# STM32U575 register map
File version: 1.4
CPU: CM33 r0p1, little endian, MPU, FPU, 4 interrupt priority bits
Registers are 32-bit, read-write, reset 0x0 unless marked. A register's access mark holds for its fields unless they carry their own. Offsets are from the block's base; [hi:lo] are bit positions; {n}, {i} and the like mark numbered series; 'fields as' and 'values as' point back to an identical list.

## FMC
Base 0x420D0400
Same registers: SEC_FMC 0x520D0400
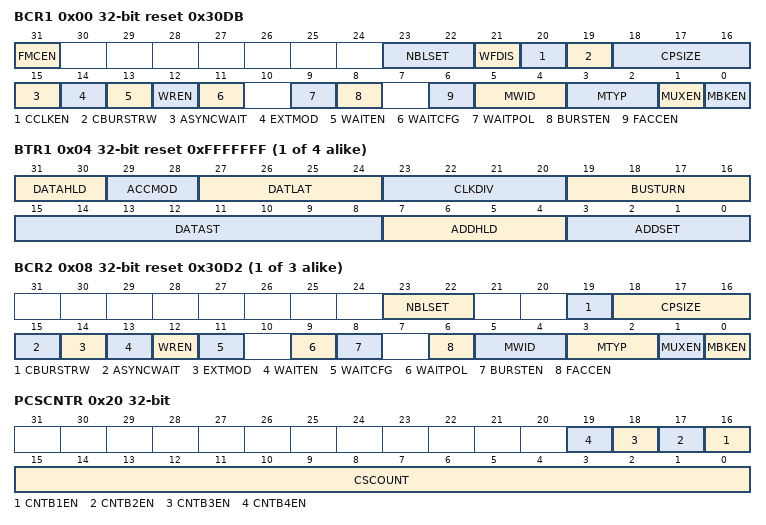
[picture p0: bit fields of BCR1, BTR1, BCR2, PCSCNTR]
0x00 BCR1 reset 0x30DB — SRAM/NOR-Flash chip-select control register for bank 1
  [31] FMCEN — FMC controller enable
  [23:22] NBLSET — Byte lane (NBL) setup
  [21] WFDIS — Write FIFO disable
  [20] CCLKEN — Continuous clock enable
  [19] CBURSTRW — Write burst enable
    0=Disabled (Write operations are always performed in asynchronous mode); 1=Enabled (Write operations are performed in synchronous mode)
  [18:16] CPSIZE — CRAM Page Size
    0=No burst split when crossing page boundary; 1=Bytes128 (128 bytes CRAM page size); 2=Bytes256 (256 bytes CRAM page size); 3=Bytes512 (512 bytes CRAM page size); 4=Bytes1024 (1024 bytes CRAM page size)
  [15] ASYNCWAIT — Wait signal during asynchronous transfers
    0=Disabled (Wait signal not used in asynchronous mode); 1=Enabled (Wait signal used even in asynchronous mode)
  [14] EXTMOD — Extended mode enable
    0=Disabled (Values inside the FMC_BWTR are not taken into account); 1=Enabled (Values inside the FMC_BWTR are taken into account)
  [13] WAITEN — Wait enable bit
    0=Disabled (Values inside the FMC_BWTR are taken into account); 1=Enabled (NWAIT signal enabled)
  [12] WREN — Write enable bit
    0=Disabled (Write operations disabled for the bank by the FMC); 1=Enabled (Write operations enabled for the bank by the FMC)
  [11] WAITCFG — Wait timing configuration
    0=BeforeWaitState (NWAIT signal is active one data cycle before wait state); 1=DuringWaitState (NWAIT signal is active during wait state)
  [9] WAITPOL — Wait signal polarity bit
    0=ActiveLow (NWAIT active low); 1=ActiveHigh (NWAIT active high)
  [8] BURSTEN — Burst enable bit
    0=Disabled (Burst mode disabled); 1=Enabled (Burst mode enabled)
  [6] FACCEN — Flash access enable
    0=Disabled (Corresponding NOR Flash memory access is disabled); 1=Enabled (Corresponding NOR Flash memory access is enabled)
  [5:4] MWID — Memory data bus width
    0=Bits8 (Memory data bus width 8 bits); 1=Bits16 (Memory data bus width 16 bits); 2=Bits32 (Memory data bus width 32 bits)
  [3:2] MTYP — Memory type
    0=SRAM (SRAM memory type); 1=PSRAM (PSRAM (CRAM) memory type); 2=Flash (NOR Flash/OneNAND Flash)
  [1] MUXEN — Address/data multiplexing enable bit
    0=Disabled (Address/Data non-multiplexed); 1=Enabled (Address/Data multiplexed on databus)
  [0] MBKEN — Memory bank enable bit
    0=Disabled (Corresponding memory bank is disabled); 1=Enabled (Corresponding memory bank is enabled)
0x04 BTR{i} (i=1..4; step 0x8) reset 0xFFFFFFF — SRAM/NOR-Flash chip-select timing register for bank {i}
  [31:30] DATAHLD — Data hold phase duration
  [29:28] ACCMOD — Access mode
    0=A (Access mode A); 1=B (Access mode B); 2=C (Access mode C); 3=D (Access mode D)
  [27:24] DATLAT — Data latency for synchronous memory
  [23:20] CLKDIV range 1..15 — Clock divide ratio (for FMC_CLK signal)
  [19:16] BUSTURN — Bus turnaround phase duration
  [15:8] DATAST range 1..255 — Data-phase duration
  [7:4] ADDHLD range 1..15 — Address-hold phase duration
  [3:0] ADDSET — Address setup phase duration
0x08 BCR{i} (i=2..4; step 0x8) reset 0x30D2 — SRAM/NOR-Flash chip-select control register for bank {i}
  [23:22] NBLSET — Byte lane (NBL) setup
  [19] CBURSTRW — Write burst enable
    values as BCR1.CBURSTRW
  [18:16] CPSIZE — CRAM Page Size
    values as BCR1.CPSIZE
  [15] ASYNCWAIT — Wait signal during asynchronous transfers
    values as BCR1.ASYNCWAIT
  [14] EXTMOD — Extended mode enable
    values as BCR1.EXTMOD
  [13] WAITEN — Wait enable bit
    values as BCR1.WAITEN
  [12] WREN — Write enable bit
    values as BCR1.WREN
  [11] WAITCFG — Wait timing configuration
    values as BCR1.WAITCFG
  [9] WAITPOL — Wait signal polarity bit
    values as BCR1.WAITPOL
  [8] BURSTEN — Burst enable bit
    values as BCR1.BURSTEN
  [6] FACCEN — Flash access enable
    values as BCR1.FACCEN
  [5:4] MWID — Memory data bus width
    values as BCR1.MWID
  [3:2] MTYP — Memory type
    values as BCR1.MTYP
  [1] MUXEN — Address/data multiplexing enable bit
    values as BCR1.MUXEN
  [0] MBKEN — Memory bank enable bit
    values as BCR1.MBKEN
0x20 PCSCNTR — PSRAM chip select counter register
  [n+15] CNTB{n}EN (n=1..4) — Counter Bank {n} enable
  [15:0] CSCOUNT — Chip select counter
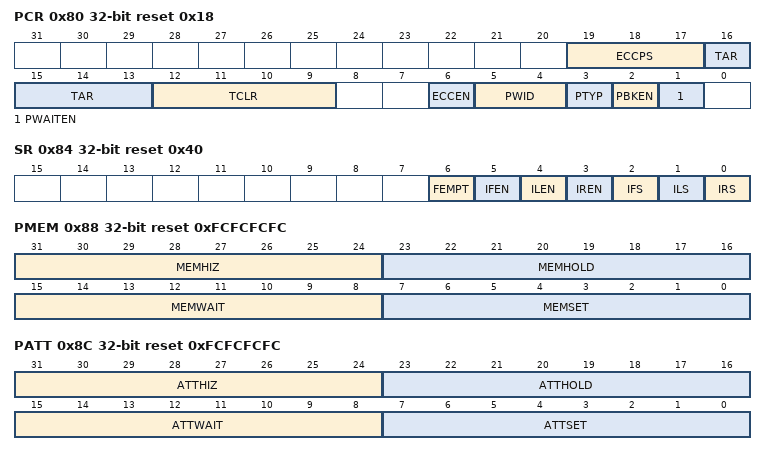
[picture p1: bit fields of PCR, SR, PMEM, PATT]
0x80 PCR reset 0x18 — NAND Flash control registers
  [19:17] ECCPS — ECC page size
    0=Bytes256 (ECC page size 256 bytes); 1=Bytes512 (ECC page size 512 bytes); 2=Bytes1024 (ECC page size 1024 bytes); 3=Bytes2048 (ECC page size 2048 bytes); 4=Bytes4096 (ECC page size 4096 bytes); 5=Bytes8192 (ECC page size 8192 bytes)
  [16:13] TAR — ALE to RE delay
  [12:9] TCLR — CLE to RE delay
  [6] ECCEN — ECC computation logic enable bit
    0=Disabled (ECC logic is disabled and reset); 1=Enabled (ECC logic is enabled)
  [5:4] PWID — Data bus width
    0=Bits8 (External memory device width 8 bits); 1=Bits16 (External memory device width 16 bits)
  [3] PTYP — Memory type
    1=NANDFlash
  [2] PBKEN — NAND Flash memory bank enable bit
    values as BCR1.MBKEN
  [1] PWAITEN — Wait feature enable bit
    0=Disabled (Wait feature disabled); 1=Enabled (Wait feature enabled)
0x84 SR access per field reset 0x40 — status and interrupt register
  [6] FEMPT ro — FIFO empty. Read-only bit that provides the status of the FIFO
    0=NotEmpty (FIFO not empty); 1=Empty (FIFO empty)
  [5] IFEN rw — Interrupt falling edge detection enable bit
    0=Disabled (Interrupt falling edge detection request disabled); 1=Enabled (Interrupt falling edge detection request enabled)
  [4] ILEN rw — Interrupt high-level detection enable bit
    0=Disabled (Interrupt high-level detection request disabled); 1=Enabled (Interrupt high-level detection request enabled)
  [3] IREN rw — Interrupt rising edge detection enable bit
    0=Disabled (Interrupt rising edge detection request disabled); 1=Enabled (Interrupt rising edge detection request enabled)
  [2] IFS rw — Interrupt falling edge status The flag is set by hardware and reset by software. Note: If this bit is written by software to 1 it will be set.
    0=DidNotOccur (Interrupt falling edge did not occur); 1=Occurred (Interrupt falling edge occurred)
  [1] ILS rw — Interrupt high-level status The flag is set by hardware and reset by software.
    0=DidNotOccur (Interrupt high-level did not occur); 1=Occurred (Interrupt high-level occurred)
  [0] IRS rw — Interrupt rising edge status The flag is set by hardware and reset by software. Note: If this bit is written by software to 1 it will be set.
    0=DidNotOccur (Interrupt rising edge did not occur); 1=Occurred (Interrupt rising edge occurred)
0x88 PMEM reset 0xFCFCFCFC — Common memory space timing register
  [31:24] MEMHIZ range 0..254 — Common memory x data bus Hi-Z time These bits define the number of KCK_FMC clock cycles during which the data bus is kept Hi-Z after the start of a NAND Flash write access to common memory space. This is only valid for write transactions:
  [23:16] MEMHOLD range 1..254 — Common memory hold time These bits define the number of KCK_FMC clock cycles for write accesses and KCK_FMC+1 clock cycles for read accesses during which the address is held (and data for write accesses) after the command is de-asserted (NWE, NOE), for NAND Flash read or write access to common memory space:
  [15:8] MEMWAIT range 1..254 — Common memory wait time These bits define the minimum number of KCK_FMC (+1) clock cycles to assert the command (NWE, NOE), for NAND Flash read or write access to common memory space. The duration of command assertion is extended if the wait signal (NWAIT) is active (low) at the end of the programmed value of KCK_FMC:
  [7:0] MEMSET range 0..254 — Common memory x setup time These bits define the number of KCK_FMC (+1) clock cycles to set up the address before the command assertion (NWE, NOE), for NAND Flash read or write access to common memory space:
0x8C PATT reset 0xFCFCFCFC — The FMC_PATT read/write register contains the timing information for NAND Flash memory bank. It is used for 8-bit accesses to the attribute memory space of the NAND Flash for the last address write access if the timing must differ from that of previous accesses (for Ready/Busy management, refer to Section20.8.5: NAND Flash prewait feature).
  [31:24] ATTHIZ range 0..254 — Attribute memory data bus Hi-Z time These bits define the number of KCK_FMC clock cycles during which the data bus is kept in Hi-Z after the start of a NAND Flash write access to attribute memory space on socket. Only valid for writ transaction:
  [23:16] ATTHOLD range 1..254 — Attribute memory hold time These bits define the number of KCK_FMC clock cycles during which the address is held (and data for write access) after the command de-assertion (NWE, NOE), for NAND Flash read or write access to attribute memory space:
  [15:8] ATTWAIT range 1..254 — Attribute memory wait time These bits define the minimum number of x KCK_FMC (+1) clock cycles to assert the command (NWE, NOE), for NAND Flash read or write access to attribute memory space. The duration for command assertion is extended if the wait signal (NWAIT) is active (low) at the end of the programmed value of KCK_FMC:
  [7:0] ATTSET range 0..254 — Attribute memory setup time These bits define the number of KCK_FMC (+1) clock cycles to set up address before the command assertion (NWE, NOE), for NAND Flash read or write access to attribute memory space:
0x94 ECCR ro — This register contain the current error correction code value computed by the ECC computation modules of the FMC NAND controller. When the CPU reads/writes the data from a NAND Flash memory page at the correct address (refer to Section20.8.6: Computation of the error correction code (ECC) in NAND Flash memory), the data read/written from/to the NAND Flash memory are processed automatically by the ECC computation module. When X bytes have been read (according to the ECCPS field in the FMC_PCR registers), the CPU must read the computed ECC value from the FMC_ECC registers. It then verifies if these computed parity data are the same as the parity value recorded in the spare area, to determine whether a page is valid, and, to correct it otherwise. The FMC_ECCR register should be cleared after being read by setting the ECCEN bit to 0. To compute a new data block, the ECCEN bit must be set to 1.
  [31:0] ECC — ECC result This field contains the value computed by the ECC computation logic. Table167 describes the contents of these bit fields.
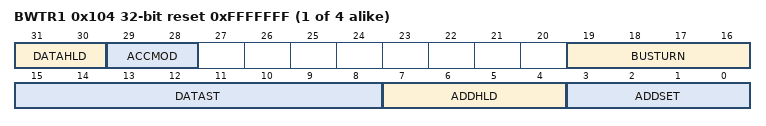
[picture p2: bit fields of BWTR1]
{0xFC+8i} BWTR{i} (i=1..4) reset 0xFFFFFFF — SRAM/NOR-Flash write timing registers {i}
  [31:30] DATAHLD — Data hold phase duration
  [29:28] ACCMOD — Access mode
    values as BTR{i}.ACCMOD
  [19:16] BUSTURN — Bus turnaround phase duration
  [15:8] DATAST range 1..255 — Data-phase duration
  [7:4] ADDHLD range 1..15 — Address-hold phase duration
  [3:0] ADDSET — Address setup phase duration
